# STM32L151 register map
File version: 1.5
CPU: CM3 r1p1, little endian, no MPU, no FPU, 4 interrupt priority bits
Registers are 32-bit, read-write, reset 0x0 unless marked. A register's access mark holds for its fields unless they carry their own. Offsets are from the block's base; [hi:lo] are bit positions; {n}, {i} and the like mark numbered series.

## RI — Routing interface
Base 0x40007C04
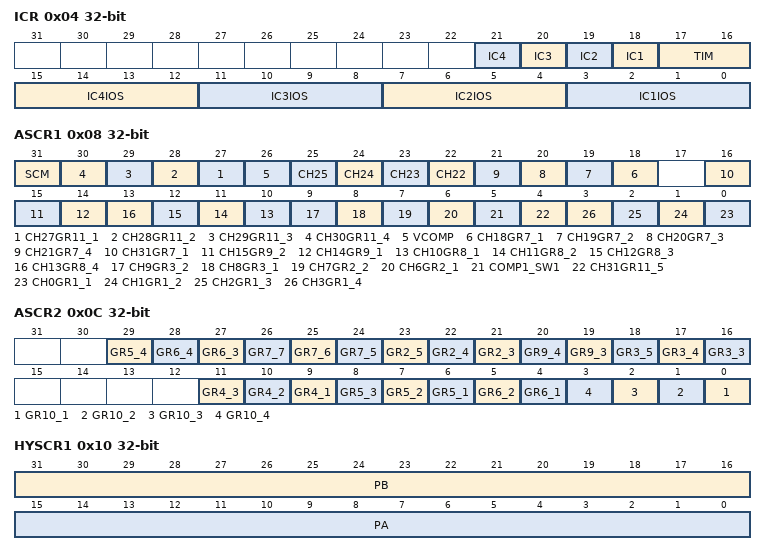
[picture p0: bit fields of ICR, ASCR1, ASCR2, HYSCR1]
0x04 ICR — RI input capture register
  [n+17] IC{n} (n=1..4)
  [17:16] TIM — Timer select bits
  [4n-1:4n-4] IC{n}IOS (n=1..4) — Input capture {n} select bits
0x08 ASCR1 — RI analog switches control register 1
  [31] SCM — Switch control mode
  [n] CH{n}GR11_{n-26} (n=27..30) — Analog switch control
  [26] VCOMP — ADC analog switch selection for internal node to comparator 1
  [n] CH{n} (n=22..25) — Analog I/O switch control of channel CH{n}
  [n] CH{n}GR7_{n-17} (n=18..21) — Analog switch control
  [16] CH31GR7_1 — Analog switch control
  [15] CH15GR9_2 — Analog switch control
  [14] CH14GR9_1 — Analog switch control
  [n] CH{n}GR8_{n-9} (n=10..13) — Analog switch control
  [9] CH9GR3_2 — Analog switch control
  [8] CH8GR3_1 — Analog switch control
  [7] CH7GR2_2 — Analog switch control
  [6] CH6GR2_1 — Analog switch control
  [5] COMP1_SW1 — Comparator 1 analog switch
  [4] CH31GR11_5 — Analog switch control
  [n] CH{n}GR1_{n+1} (n=0..3) — Analog switch control
0x0C ASCR2 — RI analog switches control register 2
  [29] GR5_4 — GR5_4 analog switch control
  [28] GR6_4 — GR6_4 analog switch control
  [27] GR6_3 — GR6_3 analog switch control
  [26] GR7_7 — GR7_7 analog switch control
  [25] GR7_6 — GR7_6 analog switch control
  [24] GR7_5 — GR7_5 analog switch control
  [23] GR2_5 — GR2_5 analog switch control
  [22] GR2_4 — GR2_4 analog switch control
  [21] GR2_3 — GR2_3 analog switch control
  [20] GR9_4 — GR9_4 analog switch control
  [19] GR9_3 — GR9_3 analog switch control
  [18] GR3_5 — GR3_5 analog switch control
  [17] GR3_4 — GR3_4 analog switch control
  [16] GR3_3 — GR3_3 analog switch control
  [11] GR4_3 — GR4_3 analog switch control
  [10] GR4_2 — GR4_2 analog switch control
  [9] GR4_1 — GR4_1 analog switch control
  [8] GR5_3 — GR5_3 analog switch control
  [7] GR5_2 — GR5_2 analog switch control
  [6] GR5_1 — GR5_1 analog switch control
  [5] GR6_2 — GR6_2 analog switch control
  [4] GR6_1 — GR6_1 analog switch control
  [n-1] GR10_{n} (n=1..4) — GR10_{n} analog switch control
0x10 HYSCR1 — RI hysteresis control register 1
  [31:16] PB — Port B hysteresis control on/off
  [15:0] PA — Port A hysteresis control on/off
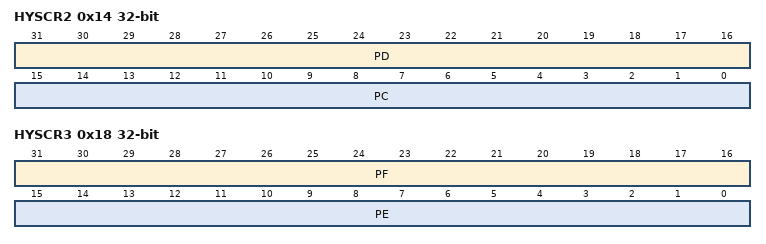
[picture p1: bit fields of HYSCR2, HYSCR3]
0x14 HYSCR2 — RI hysteresis control register 2
  [31:16] PD — Port D hysteresis control on/off
  [15:0] PC — Port C hysteresis control on/off
0x18 HYSCR3 — RI hysteresis control register 3
  [31:16] PF — Port F hysteresis control on/off
  [15:0] PE — Port E hysteresis control on/off
0x1C HYSCR4 — Hysteresis control register
  [15:0] PG — Port G hysteresis control on/off

## SPI1 — Serial peripheral interface
Base 0x40013000
Same registers: SPI2 0x40003800, SPI3 0x40003C00
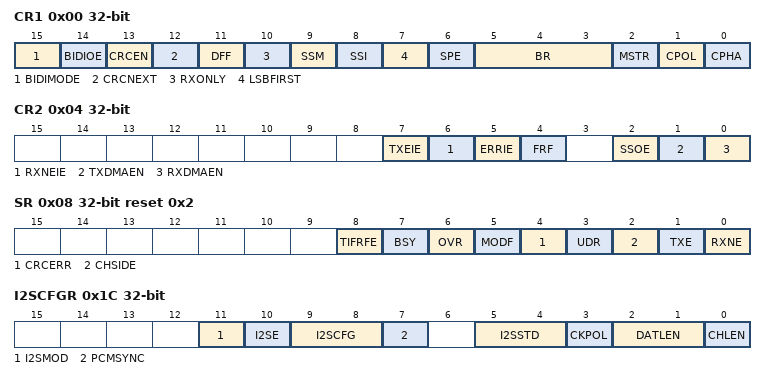
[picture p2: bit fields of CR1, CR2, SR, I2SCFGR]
0x00 CR1 — control register 1
  [15] BIDIMODE — Bidirectional data mode enable
  [14] BIDIOE — Output enable in bidirectional mode
  [13] CRCEN — Hardware CRC calculation enable
  [12] CRCNEXT — CRC transfer next
  [11] DFF — Data frame format
  [10] RXONLY — Receive only
  [9] SSM — Software slave management
  [8] SSI — Internal slave select
  [7] LSBFIRST — Frame format
  [6] SPE — SPI enable
  [5:3] BR — Baud rate control
  [2] MSTR — Master selection
  [1] CPOL — Clock polarity
  [0] CPHA — Clock phase
0x04 CR2 — control register 2
  [7] TXEIE — Tx buffer empty interrupt enable
  [6] RXNEIE — RX buffer not empty interrupt enable
  [5] ERRIE — Error interrupt enable
  [4] FRF — Frame format
  [2] SSOE — SS output enable
  [1] TXDMAEN — Tx buffer DMA enable
  [0] RXDMAEN — Rx buffer DMA enable
0x08 SR access per field reset 0x2 — status register
  [8] TIFRFE ro — TI frame format error
  [7] BSY ro — Busy flag
  [6] OVR ro — Overrun flag
  [5] MODF ro — Mode fault
  [4] CRCERR rw — CRC error flag
  [3] UDR ro — Underrun flag
  [2] CHSIDE ro — Channel side
  [1] TXE ro — Transmit buffer empty
  [0] RXNE ro — Receive buffer not empty
0x0C DR — data register
  [15:0] DR — Data register
0x10 CRCPR reset 0x7 — CRC polynomial register
  [15:0] CRCPOLY
0x14 RXCRCR ro — RX CRC register
  [15:0] RxCRC
0x18 TXCRCR ro — TX CRC register
  [15:0] TxCRC
0x1C I2SCFGR — I2S configuration register
  [11] I2SMOD — I2S mode selection
  [10] I2SE — I2S Enable
  [9:8] I2SCFG — I2S configuration mode
  [7] PCMSYNC — PCM frame synchronization
  [5:4] I2SSTD — I2S standard selection
  [3] CKPOL — Steady state clock polarity
  [2:1] DATLEN — Data length to be transferred
  [0] CHLEN — Channel length (number of bits per audio channel)
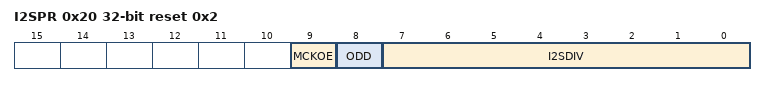
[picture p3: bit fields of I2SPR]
0x20 I2SPR reset 0x2 — I2S prescaler register
  [9] MCKOE — Master clock output enable
  [8] ODD — Odd factor for the prescaler
  [7:0] I2SDIV — I2S Linear prescaler
